# DDR32SS0_CTLPHY_WRAP_CTL_CFG_CTLCFG register map
Vendor: Texas Instruments
Registers are 32-bit, read-write, reset 0x0 unless marked. A register's access mark holds for its fields unless they carry their own. Offsets are as the file gives them; [hi:lo] are bit positions; lines under a group give offsets from that group; {n}, {i} and the like mark numbered series.

## DDR32SS0_CTLPHY_WRAP_CTL_CFG_CTLCFG (part 11 of 11)
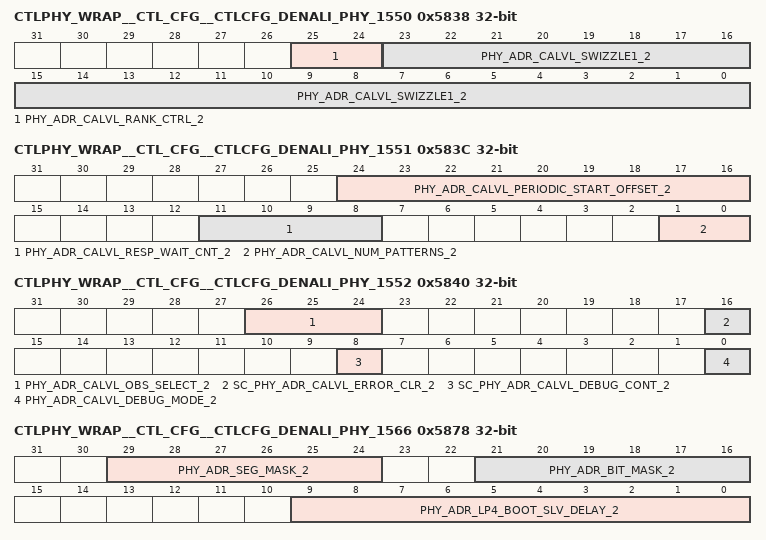
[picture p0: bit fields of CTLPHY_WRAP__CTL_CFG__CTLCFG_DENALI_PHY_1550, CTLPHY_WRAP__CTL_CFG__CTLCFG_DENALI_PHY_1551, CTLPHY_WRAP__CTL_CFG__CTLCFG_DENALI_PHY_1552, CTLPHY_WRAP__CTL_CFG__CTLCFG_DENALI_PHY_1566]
0x5838 CTLPHY_WRAP__CTL_CFG__CTLCFG_DENALI_PHY_1550
  [25:24] PHY_ADR_CALVL_RANK_CTRL_2 — CA training rank aggregation control bits for address slice 2.
  [23:0] PHY_ADR_CALVL_SWIZZLE1_2 — CA training RD DQ bit swizzle map 1 for address slice 2.
0x583C CTLPHY_WRAP__CTL_CFG__CTLCFG_DENALI_PHY_1551
  [24:16] PHY_ADR_CALVL_PERIODIC_START_OFFSET_2 — Relative offset to start periodic CALVL from previous result
  [11:8] PHY_ADR_CALVL_RESP_WAIT_CNT_2 — Number of samples to wait before sampling response during CA training for address slice 2.
  [1:0] PHY_ADR_CALVL_NUM_PATTERNS_2 — Number of patterns to use during CA training for address slice 2.
0x5840 CTLPHY_WRAP__CTL_CFG__CTLCFG_DENALI_PHY_1552 access per field
  [26:24] PHY_ADR_CALVL_OBS_SELECT_2 rw — CA bit lane to observe result from OBS0 during CA training for address slice 2.
  [16] SC_PHY_ADR_CALVL_ERROR_CLR_2 wo — Clears the CA training state machine error status for address slice 2. Set to 1 to trigger. WRITE-ONLY
  [8] SC_PHY_ADR_CALVL_DEBUG_CONT_2 wo — Allows the CA training state machine to advance [when in debug mode] for address slice 2. Set to 1 to trigger. WRITE-ONLY
  [0] PHY_ADR_CALVL_DEBUG_MODE_2 rw — Enables CA training debug mode for address slice 2. Set to 1 to enable.
0x5844 CTLPHY_WRAP__CTL_CFG__CTLCFG_DENALI_PHY_1553 ro
  [31:0] PHY_ADR_CALVL_CH0_OBS0_2 — Observation register for CA training for channel 0 slice 2. READ-ONLY
0x5848 CTLPHY_WRAP__CTL_CFG__CTLCFG_DENALI_PHY_1554 ro
  [31:0] PHY_ADR_CALVL_CH1_OBS0_2 — Observation register for CA training for channel 1 slice 2. READ-ONLY
0x584C CTLPHY_WRAP__CTL_CFG__CTLCFG_DENALI_PHY_1555 ro
  [31:0] PHY_ADR_CALVL_OBS1_2 — Observation register contains general CA training bits for slice 2. READ-ONLY
0x5850 CTLPHY_WRAP__CTL_CFG__CTLCFG_DENALI_PHY_1556 ro reset 0x100
  [31:0] PHY_ADR_CALVL_OBS2_2 — Observation register contains periodic CA training bits for slice 2. READ-ONLY
0x5854 CTLPHY_WRAP__CTL_CFG__CTLCFG_DENALI_PHY_1557
  [19:0] PHY_ADR_CALVL_FG_0_2 — CA training foreground pattern 0 for address slice 2.
0x5858 CTLPHY_WRAP__CTL_CFG__CTLCFG_DENALI_PHY_1558
  [19:0] PHY_ADR_CALVL_BG_0_2 — CA training background pattern 0 for address slice 2.
0x585C CTLPHY_WRAP__CTL_CFG__CTLCFG_DENALI_PHY_1559
  [19:0] PHY_ADR_CALVL_FG_1_2 — CA training foreground pattern 1 for address slice 2.
0x5860 CTLPHY_WRAP__CTL_CFG__CTLCFG_DENALI_PHY_1560
  [19:0] PHY_ADR_CALVL_BG_1_2 — CA training background pattern 1 for address slice 2.
0x5864 CTLPHY_WRAP__CTL_CFG__CTLCFG_DENALI_PHY_1561
  [19:0] PHY_ADR_CALVL_FG_2_2 — CA training foreground pattern 2 for address slice 2.
0x5868 CTLPHY_WRAP__CTL_CFG__CTLCFG_DENALI_PHY_1562
  [19:0] PHY_ADR_CALVL_BG_2_2 — CA training background pattern 2 for address slice 2.
0x586C CTLPHY_WRAP__CTL_CFG__CTLCFG_DENALI_PHY_1563
  [19:0] PHY_ADR_CALVL_FG_3_2 — CA training foreground pattern 3 for address slice 2.
0x5870 CTLPHY_WRAP__CTL_CFG__CTLCFG_DENALI_PHY_1564
  [19:0] PHY_ADR_CALVL_BG_3_2 — CA training background pattern 3 for address slice 2.
0x5874 CTLPHY_WRAP__CTL_CFG__CTLCFG_DENALI_PHY_1565
  [29:0] PHY_ADR_ADDR_SEL_2 — Selects which DFI address pins connect to which CA pins for LPDDR3/4 for address slice 2.
0x5878 CTLPHY_WRAP__CTL_CFG__CTLCFG_DENALI_PHY_1566
  [29:24] PHY_ADR_SEG_MASK_2 — Segment mask bit for address slice 2. Set to 1 to indicate that the bit is either CA 4 or CA 9.
  [21:16] PHY_ADR_BIT_MASK_2 — Mask bit for address slice 2. Set to 1 to indicate that the bit is used.
  [9:0] PHY_ADR_LP4_BOOT_SLV_DELAY_2 — Address target delay setting during the LPDDR4 boot frequency operation for address slice 2.
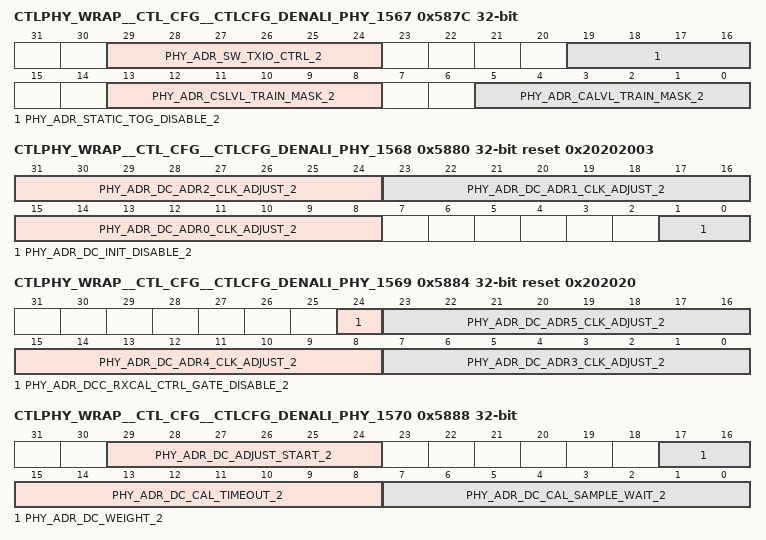
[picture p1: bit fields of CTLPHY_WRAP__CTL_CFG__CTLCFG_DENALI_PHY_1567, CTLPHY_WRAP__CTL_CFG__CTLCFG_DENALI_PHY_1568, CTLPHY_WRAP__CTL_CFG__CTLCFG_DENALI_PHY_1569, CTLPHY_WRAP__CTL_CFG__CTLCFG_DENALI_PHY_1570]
0x587C CTLPHY_WRAP__CTL_CFG__CTLCFG_DENALI_PHY_1567
  [29:24] PHY_ADR_SW_TXIO_CTRL_2 — Controls address pad output enable for address slice 2. Set to 1 to disable output enable.
  [19:16] PHY_ADR_STATIC_TOG_DISABLE_2 — Toggle control during static activity for address slice 2. Set bit to dsiable toggling, bit0: Write path delay line, bit1: Read path delay line, bit2: Read data path, bit3: clk_phy, bit4: controller delay line.
  [13:8] PHY_ADR_CSLVL_TRAIN_MASK_2 — Mask bit for CS training participation for address slice 2. Set to 1 to indicate that the bit is participating in CS training.
  [5:0] PHY_ADR_CALVL_TRAIN_MASK_2 — Mask bit for CA training participation for address slice 2. Set to 1 to indicate that the bit is participating in CA training.
0x5880 CTLPHY_WRAP__CTL_CFG__CTLCFG_DENALI_PHY_1568 reset 0x20202003
  [31:24] PHY_ADR_DC_ADR2_CLK_ADJUST_2 — Adjust value of Clock Duty Cycle Adjuster lane 2 for address slice 2.
  [23:16] PHY_ADR_DC_ADR1_CLK_ADJUST_2 — Adjust value of Clock Duty Cycle Adjuster lane 1 for address slice 2.
  [15:8] PHY_ADR_DC_ADR0_CLK_ADJUST_2 — Adjust value of Clock Duty Cycle Adjuster lane 0 for address slice 2.
  [1:0] PHY_ADR_DC_INIT_DISABLE_2 — Duty Cycle Corrector disable at initialization for address slice 2. Set to 1 to disable, bit [1] controls data path, bit [0] controls clock path.
0x5884 CTLPHY_WRAP__CTL_CFG__CTLCFG_DENALI_PHY_1569 reset 0x202020
  [24] PHY_ADR_DCC_RXCAL_CTRL_GATE_DISABLE_2 — DCC and RX_CAL clk gate disable for address slice 2. 1 = disable clk gate.
  [23:16] PHY_ADR_DC_ADR5_CLK_ADJUST_2 — Adjust value of Clock Duty Cycle Adjuster lane 5 for address slice 2.
  [15:8] PHY_ADR_DC_ADR4_CLK_ADJUST_2 — Adjust value of Clock Duty Cycle Adjuster lane 4 for address slice 2.
  [7:0] PHY_ADR_DC_ADR3_CLK_ADJUST_2 — Adjust value of Clock Duty Cycle Adjuster lane 3 for address slice 2.
0x5888 CTLPHY_WRAP__CTL_CFG__CTLCFG_DENALI_PHY_1570
  [29:24] PHY_ADR_DC_ADJUST_START_2 — DCC calibration starting value for address slice 2.
  [17:16] PHY_ADR_DC_WEIGHT_2 — DCC weighting factor base value for address slice 2.
  [15:8] PHY_ADR_DC_CAL_TIMEOUT_2 — DCC number of iterations to wait before timeout for address slice 2.
  [7:0] PHY_ADR_DC_CAL_SAMPLE_WAIT_2 — DCC cycles to wait after calibration change before sampling results for address slice 2.
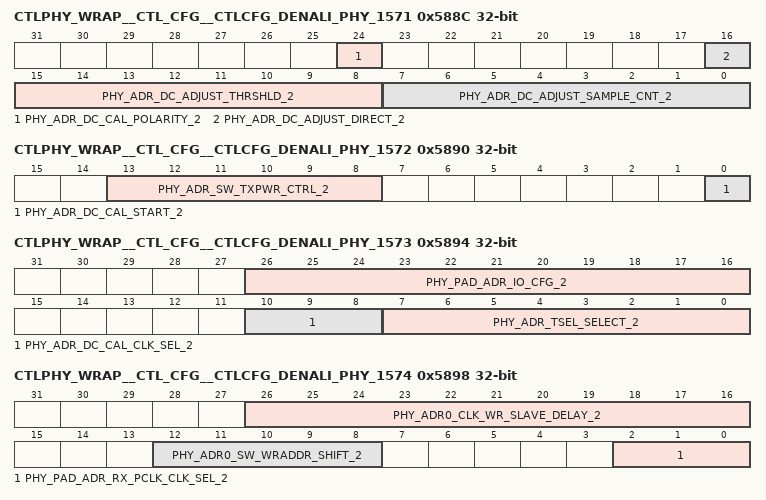
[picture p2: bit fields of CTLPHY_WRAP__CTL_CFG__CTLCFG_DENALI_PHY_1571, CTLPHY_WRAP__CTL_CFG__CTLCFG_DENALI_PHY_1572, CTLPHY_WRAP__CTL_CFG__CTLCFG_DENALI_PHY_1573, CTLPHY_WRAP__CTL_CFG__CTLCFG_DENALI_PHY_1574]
0x588C CTLPHY_WRAP__CTL_CFG__CTLCFG_DENALI_PHY_1571
  [24] PHY_ADR_DC_CAL_POLARITY_2 — DCC calibration polarity for address slice 2.
  [16] PHY_ADR_DC_ADJUST_DIRECT_2 — DCC adjust direction for address slice 2.
  [15:8] PHY_ADR_DC_ADJUST_THRSHLD_2 — DCC adjust threshold around the mid-point for address slice 2.
  [7:0] PHY_ADR_DC_ADJUST_SAMPLE_CNT_2 — DCC number of samples to take for address slice 2.
0x5890 CTLPHY_WRAP__CTL_CFG__CTLCFG_DENALI_PHY_1572
  [13:8] PHY_ADR_SW_TXPWR_CTRL_2 — Disable address output enables in deep sleep mode for address slice 2.
  [0] PHY_ADR_DC_CAL_START_2 — DCC Manual trigger for address slice 2.
0x5894 CTLPHY_WRAP__CTL_CFG__CTLCFG_DENALI_PHY_1573
  [26:16] PHY_PAD_ADR_IO_CFG_2 — Controls I/O pads for address pad for address slice 2. Bits [10:5] = Park value, bits [4] park override, bits [2:0] clk divider.
  [10:8] PHY_ADR_DC_CAL_CLK_SEL_2 — DCC CAL clock for address slice 2.
  [7:0] PHY_ADR_TSEL_SELECT_2 — Tsel select values for address slice 2.
0x5898 CTLPHY_WRAP__CTL_CFG__CTLCFG_DENALI_PHY_1574
  [26:16] PHY_ADR0_CLK_WR_SLAVE_DELAY_2 — CA bit 0 target delay setting for address slice 2.
  [12:8] PHY_ADR0_SW_WRADDR_SHIFT_2 — Manual override of CA bit 0 of automatic half_cycle_shift/cycle_shift for address slice 2. Bit [0] enables override of half_cycle_shift. Bit [1] is the half_cycle_shift value. Bit [2] enables override of cycle shift. Bits [4:3] is the cycle_shift value. For bits [4:3], clear to 0x0 for no offset, program to 0x1 for -1 cycle, program to 0x2 for +1 cycle, or program to 0x3 for -2 cycles.
  [2:0] PHY_PAD_ADR_RX_PCLK_CLK_SEL_2 — Reserved for address slice 2.
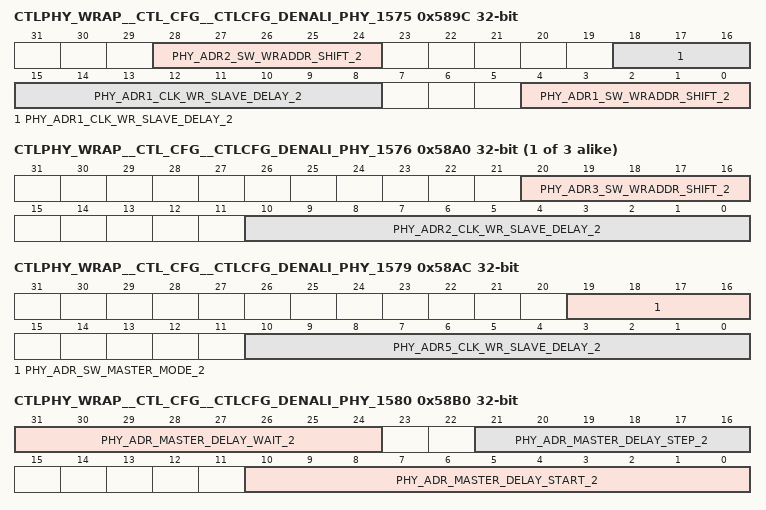
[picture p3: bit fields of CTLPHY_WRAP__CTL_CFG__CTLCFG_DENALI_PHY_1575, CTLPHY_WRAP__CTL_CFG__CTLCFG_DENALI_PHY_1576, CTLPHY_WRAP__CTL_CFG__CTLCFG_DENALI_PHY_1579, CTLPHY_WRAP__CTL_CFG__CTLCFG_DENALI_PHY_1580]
0x589C CTLPHY_WRAP__CTL_CFG__CTLCFG_DENALI_PHY_1575
  [28:24] PHY_ADR2_SW_WRADDR_SHIFT_2 — Manual override of CA bit 2 of automatic half_cycle_shift/cycle_shift for address slice 2. Bit [0] enables override of half_cycle_shift. Bit [1] is the half_cycle_shift value. Bit [2] enables override of cycle shift. Bits [4:3] is the cycle_shift value. For bits [4:3], clear to 0x0 for no offset, program to 0x1 for -1 cycle, program to 0x2 for +1 cycle, or program to 0x3 for -2 cycles.
  [18:8] PHY_ADR1_CLK_WR_SLAVE_DELAY_2 — CA bit 1 target delay setting for address slice 2.
  [4:0] PHY_ADR1_SW_WRADDR_SHIFT_2 — Manual override of CA bit 1 of automatic half_cycle_shift/cycle_shift for address slice 2. Bit [0] enables override of half_cycle_shift. Bit [1] is the half_cycle_shift value. Bit [2] enables override of cycle shift. Bits [4:3] is the cycle_shift value. For bits [4:3], clear to 0x0 for no offset, program to 0x1 for -1 cycle, program to 0x2 for +1 cycle, or program to 0x3 for -2 cycles.
{0x4000+4i} CTLPHY_WRAP__CTL_CFG__CTLCFG_DENALI_PHY_{i} (i=1576..1578)
  [20:16] PHY_ADR{i-1573}_SW_WRADDR_SHIFT_2 — Manual override of CA bit {i-1573} of automatic half_cycle_shift/cycle_shift for address slice 2. Bit [0] enables override of half_cycle_shift. Bit [1] is the half_cycle_shift value. Bit [2] enables override of cycle shift. Bits [4:3] is the cycle_shift value. For bits [4:3], clear to 0x0 for no offset, program to 0x1 for -1 cycle, program to 0x2 for +1 cycle, or program to 0x3 for -2 cycles.
  [10:0] PHY_ADR{i-1574}_CLK_WR_SLAVE_DELAY_2 — CA bit {i-1574} target delay setting for address slice 2.
0x58AC CTLPHY_WRAP__CTL_CFG__CTLCFG_DENALI_PHY_1579
  [19:16] PHY_ADR_SW_MASTER_MODE_2 — Controller delay line override settings for address slice 2. Bit [0] enables software half clock mode. Bit [1] is the software half clock mode value. Bit [2] enables software bypass mode. Bit [3] is the software bypass mode value.
  [10:0] PHY_ADR5_CLK_WR_SLAVE_DELAY_2 — CA bit 5 target delay setting for address slice 2.
0x58B0 CTLPHY_WRAP__CTL_CFG__CTLCFG_DENALI_PHY_1580
  [31:24] PHY_ADR_MASTER_DELAY_WAIT_2 — Wait cycles for controller delay line locking algorithm for address slice 2. Bits [3:0] is the cycle wait count after a calibration clock setting change. Bits [7:4] is the cycle wait count after a controller delay setting change.
  [21:16] PHY_ADR_MASTER_DELAY_STEP_2 — Incremental step size for controller delay line locking algorithm for address slice 2.
  [10:0] PHY_ADR_MASTER_DELAY_START_2 — Start value for controller delay line locking algorithm for address slice 2.
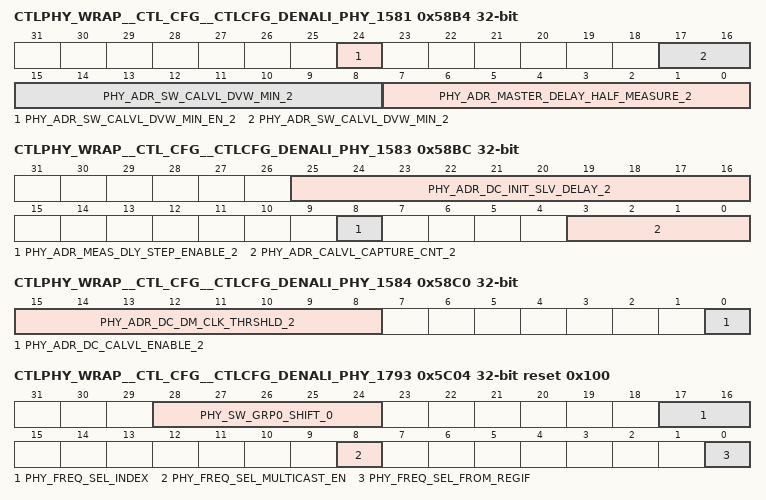
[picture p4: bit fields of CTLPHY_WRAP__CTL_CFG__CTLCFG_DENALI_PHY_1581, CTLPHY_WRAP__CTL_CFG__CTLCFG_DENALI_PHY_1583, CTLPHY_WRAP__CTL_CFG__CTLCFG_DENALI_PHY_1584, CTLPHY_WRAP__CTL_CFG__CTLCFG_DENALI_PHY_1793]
0x58B4 CTLPHY_WRAP__CTL_CFG__CTLCFG_DENALI_PHY_1581
  [24] PHY_ADR_SW_CALVL_DVW_MIN_EN_2 — Enables the software override data valid window size during CA training for address slice 2.
  [17:8] PHY_ADR_SW_CALVL_DVW_MIN_2 — Sets the software override data valid window size during CA training for address slice 2.
  [7:0] PHY_ADR_MASTER_DELAY_HALF_MEASURE_2 — Defines the number of delay line elements to be considered in determing whether to lock to a half clock cycle for the controller in address slice 2
0x58B8 CTLPHY_WRAP__CTL_CFG__CTLCFG_DENALI_PHY_1582
  [3:0] PHY_ADR_CALVL_DLY_STEP_2 — Sets the delay step size plus 1 during CA training for address slice 2.
0x58BC CTLPHY_WRAP__CTL_CFG__CTLCFG_DENALI_PHY_1583
  [25:16] PHY_ADR_DC_INIT_SLV_DELAY_2 — DCC initialization value of write ADDR target delay for address slice 2.
  [8] PHY_ADR_MEAS_DLY_STEP_ENABLE_2 — Enables delay parameter setting using phy_adr_meas_dly_step_value for address slice 2.
  [3:0] PHY_ADR_CALVL_CAPTURE_CNT_2 — Number of samples to take at each ADDR target delay setting during CA training for address slice 2.
0x58C0 CTLPHY_WRAP__CTL_CFG__CTLCFG_DENALI_PHY_1584
  [15:8] PHY_ADR_DC_DM_CLK_THRSHLD_2 — DCC clock measurement cell threshold offset for address slice 2.
  [0] PHY_ADR_DC_CALVL_ENABLE_2 — DCC enable duty cycle adjust during CA leveling for address slice 2.
0x5C00 CTLPHY_WRAP__CTL_CFG__CTLCFG_DENALI_PHY_1792
  [1:0] PHY_FREQ_SEL — Specifies which copy of the frequency-dependent timing parameters will be used by the PHY.
0x5C04 CTLPHY_WRAP__CTL_CFG__CTLCFG_DENALI_PHY_1793 reset 0x100
  [28:24] PHY_SW_GRP0_SHIFT_0 — Address slice target delay setting for address slice 4.
  [17:16] PHY_FREQ_SEL_INDEX — Selects which frequency set to update when PHY_FREQ_SEL_MULTICAST_EN is not set.
  [8] PHY_FREQ_SEL_MULTICAST_EN — When set, a register write will update parameters for all frequency sets simultaneously. Set to 1 to enable.
  [0] PHY_FREQ_SEL_FROM_REGIF — Indicates which source is used to select the frequency copy. When set to 1, the frequency select source is given by parameter PHY_FREQ_SEL from register I/F. When cleared to 0, the frequency select source is the PHY input signal dfi_frequency
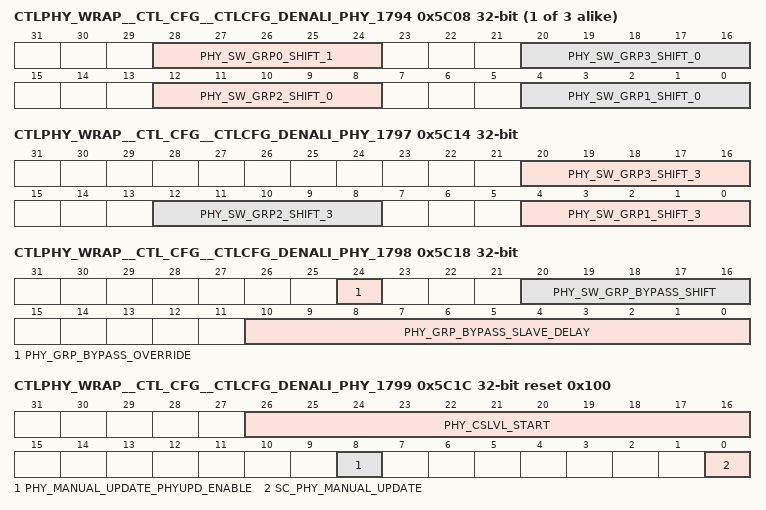
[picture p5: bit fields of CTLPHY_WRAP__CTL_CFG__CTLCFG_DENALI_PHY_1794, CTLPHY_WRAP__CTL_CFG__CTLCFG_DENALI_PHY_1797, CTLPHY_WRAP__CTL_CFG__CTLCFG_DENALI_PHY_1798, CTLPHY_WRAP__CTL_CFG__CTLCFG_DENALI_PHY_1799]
{0x4000+4i} CTLPHY_WRAP__CTL_CFG__CTLCFG_DENALI_PHY_{i} (i=1794..1796)
  [28:24] PHY_SW_GRP0_SHIFT_{i-1793} — Address slice target delay setting for address slice 4.
  [20:16] PHY_SW_GRP3_SHIFT_{i-1794} — Address slice target delay setting for address slice 4.
  [12:8] PHY_SW_GRP2_SHIFT_{i-1794} — Address slice target delay setting for address slice 4.
  [4:0] PHY_SW_GRP1_SHIFT_{i-1794} — Address slice target delay setting for address slice 4.
0x5C14 CTLPHY_WRAP__CTL_CFG__CTLCFG_DENALI_PHY_1797
  [20:16] PHY_SW_GRP3_SHIFT_3 — Address slice target delay setting for address slice 4.
  [12:8] PHY_SW_GRP2_SHIFT_3 — Address slice target delay setting for address slice 4.
  [4:0] PHY_SW_GRP1_SHIFT_3 — Address slice target delay setting for address slice 4.
0x5C18 CTLPHY_WRAP__CTL_CFG__CTLCFG_DENALI_PHY_1798
  [24] PHY_GRP_BYPASS_OVERRIDE — Address/control group slice bypass mode override setting.
  [20:16] PHY_SW_GRP_BYPASS_SHIFT — Address/control group slice bypass mode shift settings.
  [10:0] PHY_GRP_BYPASS_SLAVE_DELAY — Address/control group slice bypass mode target delay setting.
0x5C1C CTLPHY_WRAP__CTL_CFG__CTLCFG_DENALI_PHY_1799 access per field reset 0x100
  [26:16] PHY_CSLVL_START rw — Defines the CS training DDL start value.
  [8] PHY_MANUAL_UPDATE_PHYUPD_ENABLE rw — Manual update selection of all target delay line settings. Set 1 to assert phyupd_req and wait phyupd_ack to update delay line, set 0 to update delay line directly.
  [0] SC_PHY_MANUAL_UPDATE wo — Manual update of all target delay line settings. Set to 1 to trigger. WRITE-ONLY
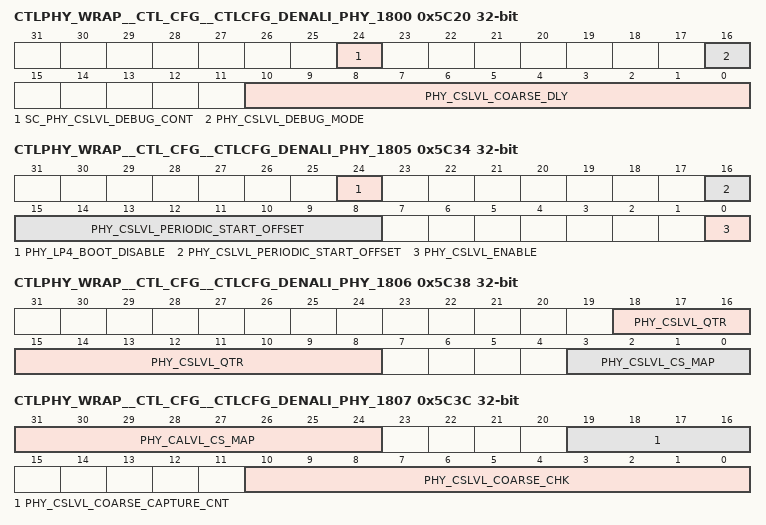
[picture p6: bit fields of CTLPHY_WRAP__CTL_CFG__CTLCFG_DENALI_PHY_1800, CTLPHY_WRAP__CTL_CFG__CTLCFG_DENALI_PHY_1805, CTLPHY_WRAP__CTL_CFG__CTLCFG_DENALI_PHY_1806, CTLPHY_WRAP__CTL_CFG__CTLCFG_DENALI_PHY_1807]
0x5C20 CTLPHY_WRAP__CTL_CFG__CTLCFG_DENALI_PHY_1800 access per field
  [24] SC_PHY_CSLVL_DEBUG_CONT wo — Allows the CS training state machine to advance [when in debug mode]. Set to 1 to trigger. WRITE-ONLY
  [16] PHY_CSLVL_DEBUG_MODE rw — Enables CS training debug mode. Set to 1 to enable.
  [10:0] PHY_CSLVL_COARSE_DLY rw — Defines the CS training DDL coarse cycle delay value.
0x5C24 CTLPHY_WRAP__CTL_CFG__CTLCFG_DENALI_PHY_1801 wo
  [0] SC_PHY_CSLVL_ERROR_CLR — Clears the CS training state machine error status. Set to 1 to trigger. WRITE-ONLY
0x5C28 CTLPHY_WRAP__CTL_CFG__CTLCFG_DENALI_PHY_1802 ro reset 0x6800000
  [31:0] PHY_CSLVL_OBS0 — Observation register for CS training delay values. READ-ONLY
0x5C2C CTLPHY_WRAP__CTL_CFG__CTLCFG_DENALI_PHY_1803 ro
  [31:0] PHY_CSLVL_OBS1 — Observation register for CS training algorithm status. READ-ONLY
0x5C30 CTLPHY_WRAP__CTL_CFG__CTLCFG_DENALI_PHY_1804 ro
  [31:0] PHY_CSLVL_OBS2 — Observation register for periodic CS training delay values. READ-ONLY
0x5C34 CTLPHY_WRAP__CTL_CFG__CTLCFG_DENALI_PHY_1805
  [24] PHY_LP4_BOOT_DISABLE — Controls the handling of the DFI frequency. When set to 1, DFI frequency 0 is considered the first operational frequency. When cleared to 0, DFI frequency 0 is the boot frequency and other DFI frequency values are operational frequencies. Must be cleared to 0 for LPDDR3 devices operating in an LPDDR4 capable configuration.
  [16:8] PHY_CSLVL_PERIODIC_START_OFFSET — Defines the relative offset from previous LE and TE to start periodic CSLVL with.
  [0] PHY_CSLVL_ENABLE — CS training enable. Set to 1 to enable CS training during CA training.
0x5C38 CTLPHY_WRAP__CTL_CFG__CTLCFG_DENALI_PHY_1806
  [18:8] PHY_CSLVL_QTR — Defines the CS training DDL 1/4 cycle delay value.
  [3:0] PHY_CSLVL_CS_MAP — CS training map. Set each CS bit to 1 to allow that CS to participate in CS training results. NOT CURRENTLY USED.
0x5C3C CTLPHY_WRAP__CTL_CFG__CTLCFG_DENALI_PHY_1807
  [31:24] PHY_CALVL_CS_MAP — Defines the slice numbers associated with each CS during CA training.
  [19:16] PHY_CSLVL_COARSE_CAPTURE_CNT — Defines the number of samples to take at each GRP target delay setting during CS training coarse CA training.
  [10:0] PHY_CSLVL_COARSE_CHK — Defines the CS training coarse CA training DDL 1/16th cycle delay value.
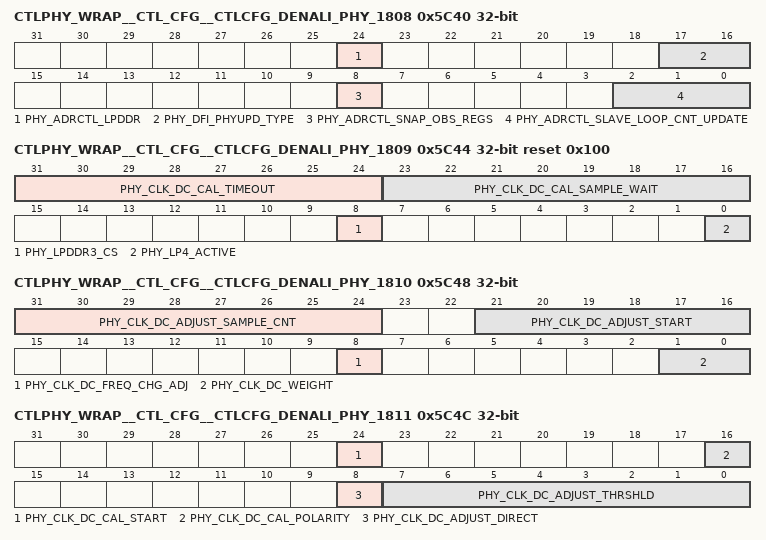
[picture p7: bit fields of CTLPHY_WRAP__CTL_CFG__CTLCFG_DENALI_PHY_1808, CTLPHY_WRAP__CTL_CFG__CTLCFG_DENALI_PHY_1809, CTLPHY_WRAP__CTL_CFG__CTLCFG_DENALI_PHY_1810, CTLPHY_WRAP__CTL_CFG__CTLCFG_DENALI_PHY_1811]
0x5C40 CTLPHY_WRAP__CTL_CFG__CTLCFG_DENALI_PHY_1808 access per field
  [24] PHY_ADRCTL_LPDDR rw — Adds a cycle of delay for the address/control slices to match the address slice.
  [17:16] PHY_DFI_PHYUPD_TYPE rw — Defines the value of the dfi_phyupd_type output signal to MC.
  [8] PHY_ADRCTL_SNAP_OBS_REGS wo — Initiates a snapshot of the internal observation registers for the address/control block. Set to 1 to trigger. WRITE-ONLY
  [2:0] PHY_ADRCTL_SLAVE_LOOP_CNT_UPDATE rw — Reserved for the address/control controller.
0x5C44 CTLPHY_WRAP__CTL_CFG__CTLCFG_DENALI_PHY_1809 reset 0x100
  [31:24] PHY_CLK_DC_CAL_TIMEOUT — Duty cycle correction maximum iteration count.
  [23:16] PHY_CLK_DC_CAL_SAMPLE_WAIT — Number of cal clock cycles to wait for a sample to be taken.
  [8] PHY_LPDDR3_CS — Alters reset state polarity for LPDDR chip selects.
  [0] PHY_LP4_ACTIVE — Indicates an LPDDR4 device is connected to the PHY.
0x5C48 CTLPHY_WRAP__CTL_CFG__CTLCFG_DENALI_PHY_1810
  [31:24] PHY_CLK_DC_ADJUST_SAMPLE_CNT — Duty cycle correction algorithm sample count per adjustment setting.
  [21:16] PHY_CLK_DC_ADJUST_START — Duty cycle correction algorithm adjustment starting value.
  [8] PHY_CLK_DC_FREQ_CHG_ADJ — Duty cycle correction during frequency change control.
  [1:0] PHY_CLK_DC_WEIGHT — Duty cycle correction weighting factor base value.
0x5C4C CTLPHY_WRAP__CTL_CFG__CTLCFG_DENALI_PHY_1811
  [24] PHY_CLK_DC_CAL_START — Duty cycle correction calibration manual start.
  [16] PHY_CLK_DC_CAL_POLARITY — Duty cycle correction algorithm measurement polarity.
  [8] PHY_CLK_DC_ADJUST_DIRECT — Duty cycle correction algorithm adjustment direction.
  [7:0] PHY_CLK_DC_ADJUST_THRSHLD — Duty cycle correction algorithm threshold delta comparison.
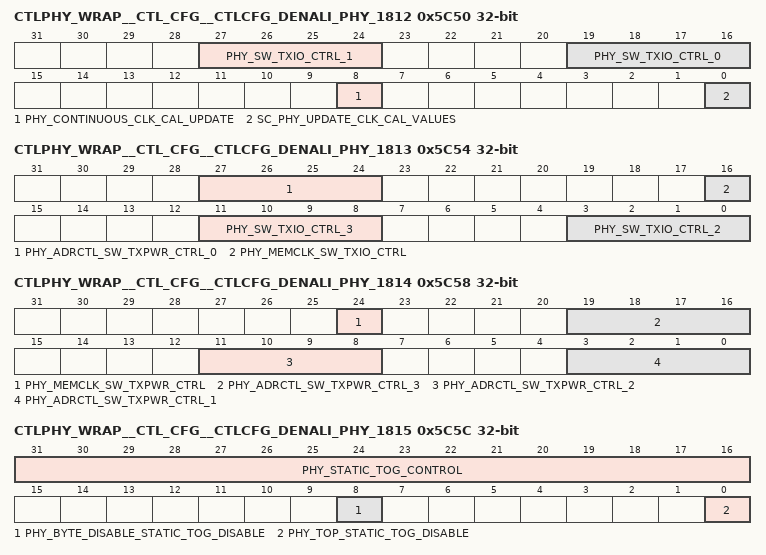
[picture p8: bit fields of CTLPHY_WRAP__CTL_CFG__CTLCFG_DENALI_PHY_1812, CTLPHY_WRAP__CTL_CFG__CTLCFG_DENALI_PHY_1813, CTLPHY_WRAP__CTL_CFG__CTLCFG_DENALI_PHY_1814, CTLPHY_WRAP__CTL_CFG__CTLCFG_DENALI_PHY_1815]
0x5C50 CTLPHY_WRAP__CTL_CFG__CTLCFG_DENALI_PHY_1812 access per field
  [27:24] PHY_SW_TXIO_CTRL_1 rw — This register is used to control if command pad [CS/RAS...] should be shutoff for TX mode.
  [19:16] PHY_SW_TXIO_CTRL_0 rw — This register is used to control if command pad [CS/RAS...] should be shutoff for TX mode.
  [8] PHY_CONTINUOUS_CLK_CAL_UPDATE rw — Continuous update of all latest PVTP,PVTN and PVTR values to the CLK IO pads. Set to 1 to keep this enabled.
  [0] SC_PHY_UPDATE_CLK_CAL_VALUES wo — Manual update of all latest PVTP,PVTN and PVTR values to the CLK IO pads. Set to 1 to trigger. WRITE-ONLY
0x5C54 CTLPHY_WRAP__CTL_CFG__CTLCFG_DENALI_PHY_1813
  [27:24] PHY_ADRCTL_SW_TXPWR_CTRL_0 — This register is used to control if address/command pad [address/CS/RAS...] should be shutoff for TX mode in deep sleep mode.
  [16] PHY_MEMCLK_SW_TXIO_CTRL — This register is used to control if clk pads should be shutoff for TX mode.
  [11:8] PHY_SW_TXIO_CTRL_3 — This register is used to control if command pad [CS/RAS...] should be shutoff for TX mode.
  [3:0] PHY_SW_TXIO_CTRL_2 — This register is used to control if command pad [CS/RAS...] should be shutoff for TX mode.
0x5C58 CTLPHY_WRAP__CTL_CFG__CTLCFG_DENALI_PHY_1814
  [24] PHY_MEMCLK_SW_TXPWR_CTRL — This register is used to control if clk pads should be shutoff for TX mode in deep sleep mode.
  [19:16] PHY_ADRCTL_SW_TXPWR_CTRL_3 — This register is used to control if address/command pad [address/CS/RAS...] should be shutoff for TX mode in deep sleep mode.
  [11:8] PHY_ADRCTL_SW_TXPWR_CTRL_2 — This register is used to control if address/command pad [address/CS/RAS...] should be shutoff for TX mode in deep sleep mode.
  [3:0] PHY_ADRCTL_SW_TXPWR_CTRL_1 — This register is used to control if address/command pad [address/CS/RAS...] should be shutoff for TX mode in deep sleep mode.
0x5C5C CTLPHY_WRAP__CTL_CFG__CTLCFG_DENALI_PHY_1815
  [31:16] PHY_STATIC_TOG_CONTROL — Clock divider to create toggle signal. Use long counter as the base.
  [8] PHY_BYTE_DISABLE_STATIC_TOG_DISABLE — Control to disable the toggle signal for data slice during static activity when dfi_data_byte_disable is asserted.
  [0] PHY_TOP_STATIC_TOG_DISABLE — Disables the generation of the toggle for static clock based paths in the PHY to prevent assymetric aging.
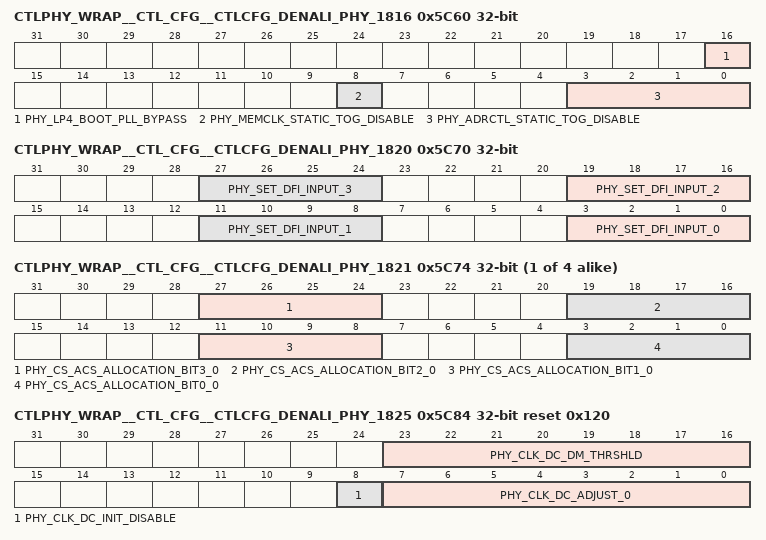
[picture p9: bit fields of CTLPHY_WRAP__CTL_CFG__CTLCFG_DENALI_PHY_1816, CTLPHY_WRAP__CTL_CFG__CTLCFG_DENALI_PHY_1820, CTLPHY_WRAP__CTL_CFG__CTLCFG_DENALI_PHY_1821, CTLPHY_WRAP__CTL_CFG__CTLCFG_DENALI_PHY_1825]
0x5C60 CTLPHY_WRAP__CTL_CFG__CTLCFG_DENALI_PHY_1816
  [16] PHY_LP4_BOOT_PLL_BYPASS — PHY clock PLL bypass select.
  [8] PHY_MEMCLK_STATIC_TOG_DISABLE — Control to disable toggle during static activity. bit0: clock disable.
  [3:0] PHY_ADRCTL_STATIC_TOG_DISABLE — Control to disable toggle during static activity. bit0: Write path delay line disable; bit1: clock disable; bit2: adrctl controller delay line disable [if exists]; bit3: adrctl misc core clk disable.[if exists]
0x5C64 CTLPHY_WRAP__CTL_CFG__CTLCFG_DENALI_PHY_1817 ro reset 0x10082650
  [31:0] PHY_CLK_SWITCH_OBS — Observation register for Clock switch state machine READ-ONLY
0x5C68 CTLPHY_WRAP__CTL_CFG__CTLCFG_DENALI_PHY_1818
  [15:0] PHY_PLL_WAIT — PHY clock PLL wait time after locking.
0x5C6C CTLPHY_WRAP__CTL_CFG__CTLCFG_DENALI_PHY_1819
  [0] PHY_SW_PLL_BYPASS — PHY clock PLL bypass select.
0x5C70 CTLPHY_WRAP__CTL_CFG__CTLCFG_DENALI_PHY_1820
  [8n+3:8n] PHY_SET_DFI_INPUT_{n} (n=0..3) — Used to indicate the default value of the adrctl slice bits.
{0x4000+4i} CTLPHY_WRAP__CTL_CFG__CTLCFG_DENALI_PHY_{i} (i=1821..1824)
  [27:24] PHY_CS_ACS_ALLOCATION_BIT3_{i-1821} — The map for which chip select is associated with each bit in the adrctl slice {i-1821}. Bit [n], 1 means cs[n]'s signal[CS/CKE/ODT/RST] is allocated on ACS_{i-1821} bit3, 0 means cs[n]'s signal[CS/CKE/ODT/RST] is not tranfser on ACS_{i-1821}, if the accroding cs[n]'s training is not enabled, need to set the value to all 1s.
  [19:16] PHY_CS_ACS_ALLOCATION_BIT2_{i-1821} — The map for which chip select is associated with each bit in the adrctl slice {i-1821}. Bit [n], 1 means cs[n]'s signal[CS/CKE/ODT/RST] is allocated on ACS_{i-1821} bit2 , 0 means cs[n]'s signal[CS/CKE/ODT/RST] is not tranfser on ACS_{i-1821}, if the accroding cs[n]'s training is not enabled, need to set the value to all 1s.
  [11:8] PHY_CS_ACS_ALLOCATION_BIT1_{i-1821} — The map for which chip select is associated with each bit in the adrctl slice {i-1821}. Bit [n], 1 means cs[n]'s signal[CS/CKE/ODT/RST] is allocated on ACS_{i-1821} bit1, 0 means cs[n]'s signal[CS/CKE/ODT/RST] is not tranfser on ACS_{i-1821}, if the accroding cs[n]'s training is not enabled, need to set the value to all 1s.
  [3:0] PHY_CS_ACS_ALLOCATION_BIT0_{i-1821} — The map for which chip select is associated with each bit in the adrctl slice {i-1821}. Bit [n], 1 means cs[n]'s signal[CS/CKE/ODT/RST] is allocated on ACS_{i-1821} bit0, 0 means cs[n]'s signal[CS/CKE/ODT/RST] is not tranfser on ACS_{i-1821}, if the accroding cs[n]'s training is not enabled, need to set the value to all 1s.
0x5C84 CTLPHY_WRAP__CTL_CFG__CTLCFG_DENALI_PHY_1825 reset 0x120
  [23:16] PHY_CLK_DC_DM_THRSHLD — Data measurement cell threshold offset.
  [8] PHY_CLK_DC_INIT_DISABLE — Disable duty cycle adjust at initialization.
  [7:0] PHY_CLK_DC_ADJUST_0 — Adjust value of Duty Cycle Adjuster for clock slice 0.
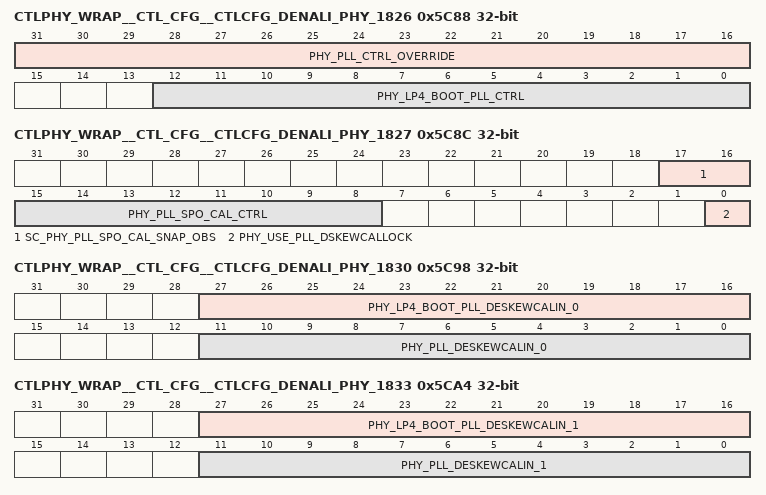
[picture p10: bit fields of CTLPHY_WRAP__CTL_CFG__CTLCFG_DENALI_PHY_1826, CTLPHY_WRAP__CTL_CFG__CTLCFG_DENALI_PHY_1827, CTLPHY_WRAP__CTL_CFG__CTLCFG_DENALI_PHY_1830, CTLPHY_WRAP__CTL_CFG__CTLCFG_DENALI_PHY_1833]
0x5C88 CTLPHY_WRAP__CTL_CFG__CTLCFG_DENALI_PHY_1826
  [31:16] PHY_PLL_CTRL_OVERRIDE — Individual PHY clock PLL control overrides.
  [12:0] PHY_LP4_BOOT_PLL_CTRL — PHY deskew PLL controls for LPDDR4 boot frequency.
0x5C8C CTLPHY_WRAP__CTL_CFG__CTLCFG_DENALI_PHY_1827 access per field
  [17:16] SC_PHY_PLL_SPO_CAL_SNAP_OBS wo — Register command to take a snapshot of PLL output. WRITE-ONLY
  [15:8] PHY_PLL_SPO_CAL_CTRL rw — PLL SPO Cal controls.
  [0] PHY_USE_PLL_DSKEWCALLOCK rw — Use DSKEWCALLOCK or not.
0x5C90 CTLPHY_WRAP__CTL_CFG__CTLCFG_DENALI_PHY_1828 ro
  [15:0] PHY_PLL_OBS_0 — PHY TOP level clock PLL_0 observe values. READ-ONLY
0x5C94 CTLPHY_WRAP__CTL_CFG__CTLCFG_DENALI_PHY_1829 ro
  [16:0] PHY_PLL_SPO_CAL_OBS_0 — PHY TOP level PLL_0 SPO Cal observe values. READ-ONLY
0x5C98 CTLPHY_WRAP__CTL_CFG__CTLCFG_DENALI_PHY_1830
  [27:16] PHY_LP4_BOOT_PLL_DESKEWCALIN_0 — PHY TOP level PLL_0 lpddr4 boot deskewcal in values.
  [11:0] PHY_PLL_DESKEWCALIN_0 — PHY TOP level PLL_0 deskewcal in values.
0x5C9C CTLPHY_WRAP__CTL_CFG__CTLCFG_DENALI_PHY_1831 ro
  [15:0] PHY_PLL_OBS_1 — PHY TOP level clock PLL_1 observe values. READ-ONLY
0x5CA0 CTLPHY_WRAP__CTL_CFG__CTLCFG_DENALI_PHY_1832 ro
  [16:0] PHY_PLL_SPO_CAL_OBS_1 — PHY TOP level PLL_1 SPO Cal observe values. READ-ONLY
0x5CA4 CTLPHY_WRAP__CTL_CFG__CTLCFG_DENALI_PHY_1833
  [27:16] PHY_LP4_BOOT_PLL_DESKEWCALIN_1 — PHY TOP level PLL_1 lpddr4 boot deskewcal in values.
  [11:0] PHY_PLL_DESKEWCALIN_1 — PHY TOP level PLL_1 deskewcal in values.
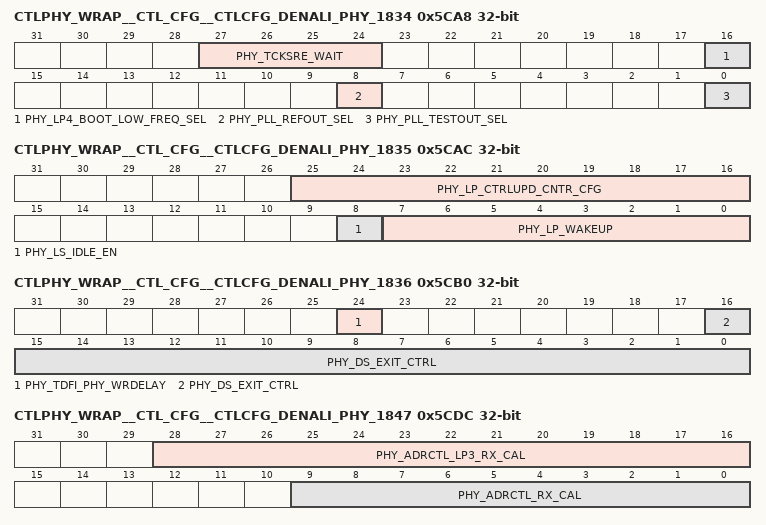
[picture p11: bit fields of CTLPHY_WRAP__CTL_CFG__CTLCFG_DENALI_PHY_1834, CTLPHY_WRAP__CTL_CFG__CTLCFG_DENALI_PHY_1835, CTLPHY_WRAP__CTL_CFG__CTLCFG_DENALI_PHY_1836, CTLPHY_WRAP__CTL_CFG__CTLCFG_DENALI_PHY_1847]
0x5CA8 CTLPHY_WRAP__CTL_CFG__CTLCFG_DENALI_PHY_1834
  [27:24] PHY_TCKSRE_WAIT — Specifies the number of cycles the PHY should wait before turning off the PLL for a deep sleep or DFS event.
  [16] PHY_LP4_BOOT_LOW_FREQ_SEL — Control the PLL domain enter/exit from the negative clock edge for LPDDR4 boot frequency.
  [8] PHY_PLL_REFOUT_SEL — PHY PLL refout select.
  [0] PHY_PLL_TESTOUT_SEL — PHY PLL testout select.
0x5CAC CTLPHY_WRAP__CTL_CFG__CTLCFG_DENALI_PHY_1835
  [25:16] PHY_LP_CTRLUPD_CNTR_CFG — Specifies the number of cycles the PHY takes from light sleep req deassert to ack deassert in low power mode.
  [8] PHY_LS_IDLE_EN — Indicates the Reduced Idle Power State is enabled in low power mode.
  [7:0] PHY_LP_WAKEUP — Specifies the number of cycles the PHY takes to wakeup in low power mode.
0x5CB0 CTLPHY_WRAP__CTL_CFG__CTLCFG_DENALI_PHY_1836
  [24] PHY_TDFI_PHY_WRDELAY — DFI timing parameter TDFI_PHY_WRDELAY.
  [16:0] PHY_DS_EXIT_CTRL — Controls to reduce the deep sleep exit latency, when bit 16 is 1 deep sleep exit ack won't wait controller delay line lock.
0x5CB4 CTLPHY_WRAP__CTL_CFG__CTLCFG_DENALI_PHY_1837 reset 0x4410
  [17:0] PHY_PAD_FDBK_TERM — Controls term settings for gate feedback pads.
0x5CB8 CTLPHY_WRAP__CTL_CFG__CTLCFG_DENALI_PHY_1838 reset 0x4410
  [16:0] PHY_PAD_DATA_TERM — Controls term settings for data pads.
0x5CBC CTLPHY_WRAP__CTL_CFG__CTLCFG_DENALI_PHY_1839 reset 0x4410
  [16:0] PHY_PAD_DQS_TERM — Controls term settings for dqs pads.
0x5CC0 CTLPHY_WRAP__CTL_CFG__CTLCFG_DENALI_PHY_1840 reset 0x4410
  [17:0] PHY_PAD_ADDR_TERM — Controls term settings for the address/control pads.
0x5CC4 CTLPHY_WRAP__CTL_CFG__CTLCFG_DENALI_PHY_1841 reset 0x4410
  [17:0] PHY_PAD_CLK_TERM — Controls term settings for clock pads.
0x5CC8 CTLPHY_WRAP__CTL_CFG__CTLCFG_DENALI_PHY_1842 reset 0x4410
  [17:0] PHY_PAD_ERR_TERM — Controls term settings for error pads.
0x5CCC CTLPHY_WRAP__CTL_CFG__CTLCFG_DENALI_PHY_1843 reset 0x4410
  [17:0] PHY_PAD_CKE_TERM — Controls term settings for cke pads.
0x5CD0 CTLPHY_WRAP__CTL_CFG__CTLCFG_DENALI_PHY_1844 reset 0x4410
  [17:0] PHY_PAD_RST_TERM — Controls term settings for reset_n pads.
0x5CD4 CTLPHY_WRAP__CTL_CFG__CTLCFG_DENALI_PHY_1845 reset 0x4410
  [17:0] PHY_PAD_CS_TERM — Controls term settings for cs pads.
0x5CD8 CTLPHY_WRAP__CTL_CFG__CTLCFG_DENALI_PHY_1846 reset 0x4410
  [17:0] PHY_PAD_ODT_TERM — Controls term settings for odt pads.
0x5CDC CTLPHY_WRAP__CTL_CFG__CTLCFG_DENALI_PHY_1847
  [28:16] PHY_ADRCTL_LP3_RX_CAL — PHY CKE/RESET_N RX calibration controls.
  [9:0] PHY_ADRCTL_RX_CAL — PHY address/control RX calibration controls.
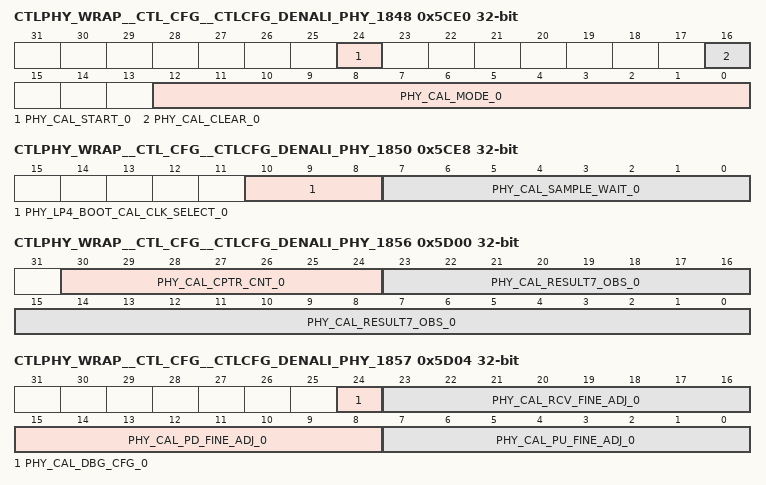
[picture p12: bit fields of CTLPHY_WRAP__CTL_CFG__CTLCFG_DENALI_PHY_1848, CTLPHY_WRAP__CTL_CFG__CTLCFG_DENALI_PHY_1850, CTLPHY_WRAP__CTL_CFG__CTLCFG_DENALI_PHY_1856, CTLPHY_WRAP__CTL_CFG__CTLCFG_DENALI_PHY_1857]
0x5CE0 CTLPHY_WRAP__CTL_CFG__CTLCFG_DENALI_PHY_1848 access per field
  [24] PHY_CAL_START_0 wo — Manual start for the pad calibration state machine for block 0. Set to 1 to trigger. WRITE-ONLY
  [16] PHY_CAL_CLEAR_0 wo — Clear the pad calibration state machine and results for block 0. Set to 1 to trigger. WRITE-ONLY
  [12:0] PHY_CAL_MODE_0 rw — Pad calibration mode bits for block 0. Bit [0] disables pad calibration upon initialization. Bit [1] enables automatic interval based calibration. Bits [3:2] set the base interval for the interval counter. Bits [7:4] are direct connections to pad control signals.
0x5CE4 CTLPHY_WRAP__CTL_CFG__CTLCFG_DENALI_PHY_1849
  [31:0] PHY_CAL_INTERVAL_COUNT_0 — Pad calibration interval counter compare value for block 0.
0x5CE8 CTLPHY_WRAP__CTL_CFG__CTLCFG_DENALI_PHY_1850
  [10:8] PHY_LP4_BOOT_CAL_CLK_SELECT_0 — Pad calibration pad clock frequency select setting for LPDDR4 boot frequency for block 0.
  [7:0] PHY_CAL_SAMPLE_WAIT_0 — Pad calibration state machine wait count in pad clock cycles for block 0.
0x5CEC CTLPHY_WRAP__CTL_CFG__CTLCFG_DENALI_PHY_1851 ro
  [23:0] PHY_CAL_RESULT_OBS_0 — Pad calibration results observation values for block 0. READ-ONLY
0x5CF0 CTLPHY_WRAP__CTL_CFG__CTLCFG_DENALI_PHY_1852 ro
  [23:0] PHY_CAL_RESULT2_OBS_0 — Pad calibration results [CKE/RESET_N] observation values for block 0. READ-ONLY
0x5CF4 CTLPHY_WRAP__CTL_CFG__CTLCFG_DENALI_PHY_1853 ro
  [23:0] PHY_CAL_RESULT4_OBS_0 — Pad calibration pass1 shadow results observation values for block 0. READ-ONLY
0x5CF8 CTLPHY_WRAP__CTL_CFG__CTLCFG_DENALI_PHY_1854 ro
  [23:0] PHY_CAL_RESULT5_OBS_0 — Pad calibration pass2 shadow results observation values for block 0. READ-ONLY
0x5CFC CTLPHY_WRAP__CTL_CFG__CTLCFG_DENALI_PHY_1855 ro
  [23:0] PHY_CAL_RESULT6_OBS_0 — Pad calibration internal results observation delta values for block 0. READ-ONLY
0x5D00 CTLPHY_WRAP__CTL_CFG__CTLCFG_DENALI_PHY_1856 access per field
  [30:24] PHY_CAL_CPTR_CNT_0 rw — defines sample capture number in pad calibration process
  [23:0] PHY_CAL_RESULT7_OBS_0 ro — Pad calibration internal results observation delta values for block 0. READ-ONLY
0x5D04 CTLPHY_WRAP__CTL_CFG__CTLCFG_DENALI_PHY_1857
  [24] PHY_CAL_DBG_CFG_0 — defines debug configuration in pad calibration process
  [23:16] PHY_CAL_RCV_FINE_ADJ_0 — defines adjustment for RCV code in pad calibration process
  [15:8] PHY_CAL_PD_FINE_ADJ_0 — defines adjustment for PD code in pad calibration process
  [7:0] PHY_CAL_PU_FINE_ADJ_0 — defines adjustment for PU code in pad calibration process
0x5D08 CTLPHY_WRAP__CTL_CFG__CTLCFG_DENALI_PHY_1858 wo
  [0] SC_PHY_PAD_DBG_CONT_0 — Allows the pad calibration state machine to advance [when in debug mode] for slice 0. Set to 1 to trigger. WRITE-ONLY
0x5D0C CTLPHY_WRAP__CTL_CFG__CTLCFG_DENALI_PHY_1859 ro
  [31:0] PHY_CAL_RESULT3_OBS_0 — Pad calibration results first/last0/1 observation values for block 0. READ-ONLY
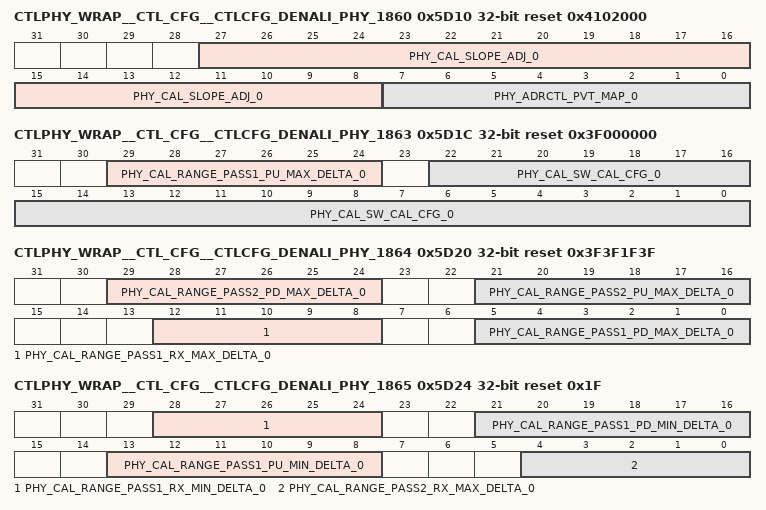
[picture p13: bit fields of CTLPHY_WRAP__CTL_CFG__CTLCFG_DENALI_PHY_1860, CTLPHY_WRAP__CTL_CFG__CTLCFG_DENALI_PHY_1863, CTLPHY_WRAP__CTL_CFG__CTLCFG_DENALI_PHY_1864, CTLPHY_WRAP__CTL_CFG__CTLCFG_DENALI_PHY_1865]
0x5D10 CTLPHY_WRAP__CTL_CFG__CTLCFG_DENALI_PHY_1860 reset 0x4102000
  [27:8] PHY_CAL_SLOPE_ADJ_0 — defines slope configure in pad calibration process
  [7:0] PHY_ADRCTL_PVT_MAP_0 — defines slope configure in pad calibration process
0x5D14 CTLPHY_WRAP__CTL_CFG__CTLCFG_DENALI_PHY_1861 reset 0x41020
  [19:0] PHY_CAL_SLOPE_ADJ_PASS2_0 — defines slope configure for pass2 in pad calibration process
0x5D18 CTLPHY_WRAP__CTL_CFG__CTLCFG_DENALI_PHY_1862 reset 0xC98C98
  [24:0] PHY_CAL_TWO_PASS_CFG_0 — defines cal_en configure in pad calibration process
0x5D1C CTLPHY_WRAP__CTL_CFG__CTLCFG_DENALI_PHY_1863 reset 0x3F000000
  [29:24] PHY_CAL_RANGE_PASS1_PU_MAX_DELTA_0 — Pad calibration pass1 pu results won't update if out of max delta range .
  [22:0] PHY_CAL_SW_CAL_CFG_0 — defines firmware based pad calibration process
0x5D20 CTLPHY_WRAP__CTL_CFG__CTLCFG_DENALI_PHY_1864 reset 0x3F3F1F3F
  [29:24] PHY_CAL_RANGE_PASS2_PD_MAX_DELTA_0 — Pad calibration pass2 pd results won't update if out of max delta range .
  [21:16] PHY_CAL_RANGE_PASS2_PU_MAX_DELTA_0 — Pad calibration pass2 pu results won't update if out of max delta range .
  [12:8] PHY_CAL_RANGE_PASS1_RX_MAX_DELTA_0 — Pad calibration pass1 rx results won't update if out of max delta range .
  [5:0] PHY_CAL_RANGE_PASS1_PD_MAX_DELTA_0 — Pad calibration pass1 pd results won't update if out of max delta range .
0x5D24 CTLPHY_WRAP__CTL_CFG__CTLCFG_DENALI_PHY_1865 reset 0x1F
  [28:24] PHY_CAL_RANGE_PASS1_RX_MIN_DELTA_0 — Pad calibration pass1 rx results won't update if out of min delta range .
  [21:16] PHY_CAL_RANGE_PASS1_PD_MIN_DELTA_0 — Pad calibration pass1 pd results won't update if out of min delta range .
  [13:8] PHY_CAL_RANGE_PASS1_PU_MIN_DELTA_0 — Pad calibration pass1 pu results won't update if out of min delta range .
  [4:0] PHY_CAL_RANGE_PASS2_RX_MAX_DELTA_0 — Pad calibration pass2 rx results won't update if out of max delta range .
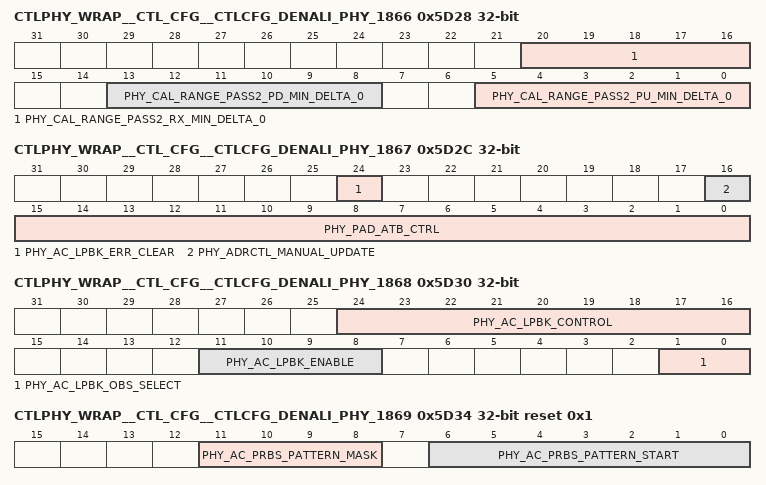
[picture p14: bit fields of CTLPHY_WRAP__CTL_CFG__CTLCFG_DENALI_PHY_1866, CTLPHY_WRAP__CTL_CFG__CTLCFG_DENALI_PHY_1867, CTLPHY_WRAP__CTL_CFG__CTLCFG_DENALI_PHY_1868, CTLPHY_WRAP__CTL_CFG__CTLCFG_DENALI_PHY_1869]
0x5D28 CTLPHY_WRAP__CTL_CFG__CTLCFG_DENALI_PHY_1866
  [20:16] PHY_CAL_RANGE_PASS2_RX_MIN_DELTA_0 — Pad calibration pass2 rx results won't update if out of min delta range .
  [13:8] PHY_CAL_RANGE_PASS2_PD_MIN_DELTA_0 — Pad calibration pass2 pd results won't update if out of min delta range .
  [5:0] PHY_CAL_RANGE_PASS2_PU_MIN_DELTA_0 — Pad calibration pass2 pu results won't update if out of min delta range .
0x5D2C CTLPHY_WRAP__CTL_CFG__CTLCFG_DENALI_PHY_1867 access per field
  [24] PHY_AC_LPBK_ERR_CLEAR wo — Address/control loopback error clear. Set to 1 to clear error. WRITE-ONLY
  [16] PHY_ADRCTL_MANUAL_UPDATE wo — Address/control manual update of target delay lines. Set to 1 to update. WRITE-ONLY
  [15:0] PHY_PAD_ATB_CTRL rw — Pad ATB control settings. Bit [0] is the enable signal. Bits [5:1] are the ATB data signals. Bits [15:8] are the 1 hot select for which pad is selected.
0x5D30 CTLPHY_WRAP__CTL_CFG__CTLCFG_DENALI_PHY_1868
  [24:16] PHY_AC_LPBK_CONTROL — Address/control slice loopback control setting.
  [11:8] PHY_AC_LPBK_ENABLE — Loopback enable for the address/control slices.
  [1:0] PHY_AC_LPBK_OBS_SELECT — Select value to map an individual loopback address/control slice observation register to the global observation register.
0x5D34 CTLPHY_WRAP__CTL_CFG__CTLCFG_DENALI_PHY_1869 reset 0x1
  [11:8] PHY_AC_PRBS_PATTERN_MASK — PRBS7 mask signal for address/control slice.
  [6:0] PHY_AC_PRBS_PATTERN_START — PRBS7 start pattern for address/control slice.
0x5D38 CTLPHY_WRAP__CTL_CFG__CTLCFG_DENALI_PHY_1870 ro
  [31:0] PHY_AC_LPBK_RESULT_OBS — Observation register for the loopback address/control slices. READ-ONLY
0x5D3C CTLPHY_WRAP__CTL_CFG__CTLCFG_DENALI_PHY_1871
  [21:16] PHY_AC_CLK_LPBK_CONTROL — Mem clk block loopback control setting.
  [8] PHY_AC_CLK_LPBK_ENABLE — Loopback enable for mem clk blocks.
  [0] PHY_AC_CLK_LPBK_OBS_SELECT — Select value to map an individual loopback mem clk block observation register to the global observation register.
0x5D40 CTLPHY_WRAP__CTL_CFG__CTLCFG_DENALI_PHY_1872 access per field
  [24] PHY_TOP_PWR_RDC_DISABLE rw — top param power reduction disable.
  [16] PHY_AC_PWR_RDC_DISABLE rw — ac slice power reduction disable.
  [15:0] PHY_AC_CLK_LPBK_RESULT_OBS ro — Observation register for loopback mem clk blocks. READ-ONLY
0x5D44 CTLPHY_WRAP__CTL_CFG__CTLCFG_DENALI_PHY_1873
  [0] PHY_AC_SLV_DLY_CTRL_GATE_DISABLE — ac slice slv_dly_control block power reduction disable.
0x5D48 CTLPHY_WRAP__CTL_CFG__CTLCFG_DENALI_PHY_1874
  [31:0] PHY_DATA_BYTE_ORDER_SEL — Used to define the data slice's byte swap for CA bits 7:0.
0x5D4C CTLPHY_WRAP__CTL_CFG__CTLCFG_DENALI_PHY_1875
  [26:24] PHY_ADR_DISABLE — Disable the unused adr slice to save power.
  [20:16] PHY_CALVL_DEVICE_MAP — Define which device's DQ feedback data bits should be used during CA training
  [8] PHY_LPDDR4_CONNECT — PHY is connected to LPDDR4 devices
  [7:0] PHY_DATA_BYTE_ORDER_SEL_HIGH — Used to define the data slice's byte swap for CA bits 9:8.
0x5D50 CTLPHY_WRAP__CTL_CFG__CTLCFG_DENALI_PHY_1876
  [8n+1:8n] PHY_ADRCTL_MSTR_DLY_ENC_SEL_{n} (n=0..3) — Select adrctl_mstr_dly_enc for the address/control slice {n} .
0x5D54 CTLPHY_WRAP__CTL_CFG__CTLCFG_DENALI_PHY_1877
  [31:0] PHY_DDL_AC_ENABLE — PHY Address/Control DDL BIST mode enable.
0x5D58 CTLPHY_WRAP__CTL_CFG__CTLCFG_DENALI_PHY_1878
  [25:0] PHY_DDL_AC_MODE — PHY Address/Control DDL BIST mode.
0x5D5C CTLPHY_WRAP__CTL_CFG__CTLCFG_DENALI_PHY_1879
  [23:16] PHY_DDL_TRACK_UPD_THRESHOLD_AC — Specify threshold value for PHY init update tracking for AC slice.
  [10:8] PHY_INIT_UPDATE_CONFIG — PHY init update function configuration.
  [5:0] PHY_DDL_AC_MASK — PHY Address/Control DDL BIST mask.
0x5D60 CTLPHY_WRAP__CTL_CFG__CTLCFG_DENALI_PHY_1880
  [26:24] PHY_ERR_STATUS — PHY ERROR information.
  [18:16] PHY_ERR_MASK_EN — PHY ERROR information report mask enable.
  [15:0] PHY_CA_PARITY_ERR_PULSE_MIN — PHY alert_n pulse width minimux value for CA parity error.
{0x4000+4i} CTLPHY_WRAP__CTL_CFG__CTLCFG_DENALI_PHY_{i} ro (i=1881..1884)
  [31:0] PHY_DS{i-1881}_DQS_ERR_COUNTER — PHY DATA SLICE {i-1881} DQS ERROR counter.
0x5D74 CTLPHY_WRAP__CTL_CFG__CTLCFG_DENALI_PHY_1885 access per field reset 0x2
  [27:24] PHY_DS_INIT_COMPLETE_OBS ro — Observation register for dfi_init_complete for data slice. Bit0 is for data_slice0; bit1 is for data_slice 1,... READ-ONLY.
  [19:8] PHY_AC_INIT_COMPLETE_OBS ro — Observation register for dfi_init_complete for adr and ac slice. Bit 0 is for dfi_init_complete for all slices. Bit[7:4] is for adr slice, bit4 is adr_slice0..., if the adr slice number is 3, bit7 is 0. Bit8 is for ac_slice0; bit9 is for ac_slice 1,... READ-ONLY.
  [1:0] PHY_DLL_RST_EN rw — PHY DDL reset software interface enable.
0x5D78 CTLPHY_WRAP__CTL_CFG__CTLCFG_DENALI_PHY_1886
  [28:24] PHY_GRP_SLV_DLY_ENC_OBS_SELECT — Select value to map an individual address/control group slice target delay to the encoded value observation register.
  [16] PHY_AC_DCC_RXCAL_CTRL_GATE_DISABLE — Memory clock bit slice DCC block power reduction disable.
  [8] PHY_ERR_IE — Control the IE signal of IO error pad.
  [0] PHY_UPDATE_MASK — Control to disable the generation of dfi_phyupd_req and use of dfi_ctrlupd_req. If this is 0 the PHY is normal mode; if this is 1, the PHY will not respond to dfi_ctrlupd_req or not to send dfi_phyupd_req
0x5D7C CTLPHY_WRAP__CTL_CFG__CTLCFG_DENALI_PHY_1887 access per field
  [26:24] PHY_GRP_SHIFT_OBS ro — Observation register for the address/control group automatic half cycle and cycle shift values. READ-ONLY
  [18:8] PHY_GRP_SLV_DLY_ENC_OBS ro — Observation register for all address/control group slice target delay encoded values. READ-ONLY
  [3:0] PHY_GRP_SHIFT_OBS_SELECT rw — Select value to map an individual address/control group slice automatic cycle/half_cycle shift settings to the observation register.
0x5D80 CTLPHY_WRAP__CTL_CFG__CTLCFG_DENALI_PHY_1888
  [17:0] PHY_PAD_CAL_IO_CFG_0 — Pad calibration Controls PCLK/PARK pin and vref switch.
0x5D84 CTLPHY_WRAP__CTL_CFG__CTLCFG_DENALI_PHY_1889
  [26:24] PHY_PAD_ACS_RX_PCLK_CLK_SEL — Controls rx_pclk clk selection for acs pad.
  [17:0] PHY_PAD_ACS_IO_CFG — Controls PCLK/PARK pin for acs pad.
0x5D88 CTLPHY_WRAP__CTL_CFG__CTLCFG_DENALI_PHY_1890
  [0] PHY_PLL_BYPASS — PHY clock PLL bypass select.
0x5D8C CTLPHY_WRAP__CTL_CFG__CTLCFG_DENALI_PHY_1891
  [16] PHY_LOW_FREQ_SEL — Enables the PHY to enter/exit the PLL domain from the negative clock edge. Set to 1 at low frequencies to enable.
  [12:0] PHY_PLL_CTRL — PHY clock PLL controls.
0x5D90 CTLPHY_WRAP__CTL_CFG__CTLCFG_DENALI_PHY_1892
  [27:24] PHY_CSLVL_DLY_STEP — Sets the delay step size plus 1 during CS training.
  [19:16] PHY_CSLVL_CAPTURE_CNT — Defines the number of samples to take at each GRP target delay setting during CS training.
  [11:0] PHY_PAD_VREF_CTRL_AC — Pad VREF control settings for the address/control.
0x5D94 CTLPHY_WRAP__CTL_CFG__CTLCFG_DENALI_PHY_1893
  [24] PHY_LVL_MEAS_DLY_STEP_ENABLE — Enables the phy_adr_meas_dly_step_value to be used instead of the phy_cslvl_dly_step parameter.
  [16] PHY_SW_CSLVL_DVW_MIN_EN — Enables the software override data valid window size during CS training.
  [9:0] PHY_SW_CSLVL_DVW_MIN — Sets the software override data valid window size during CS training.
0x5D98 CTLPHY_WRAP__CTL_CFG__CTLCFG_DENALI_PHY_1894
  [26:16] PHY_GRP1_SLAVE_DELAY_0 — Address slice target delay setting for address slice 1.
  [10:0] PHY_GRP0_SLAVE_DELAY_0 — Address slice target delay setting for address slice 0.
0x5D9C CTLPHY_WRAP__CTL_CFG__CTLCFG_DENALI_PHY_1895
  [26:16] PHY_GRP3_SLAVE_DELAY_0 — Address slice target delay setting for address slice 3.
  [10:0] PHY_GRP2_SLAVE_DELAY_0 — Address slice target delay setting for address slice 2.
0x5DA0 CTLPHY_WRAP__CTL_CFG__CTLCFG_DENALI_PHY_1896
  [26:16] PHY_GRP1_SLAVE_DELAY_1 — Address slice target delay setting for address slice 1.
  [10:0] PHY_GRP0_SLAVE_DELAY_1 — Address slice target delay setting for address slice 0.
0x5DA4 CTLPHY_WRAP__CTL_CFG__CTLCFG_DENALI_PHY_1897
  [26:16] PHY_GRP3_SLAVE_DELAY_1 — Address slice target delay setting for address slice 3.
  [10:0] PHY_GRP2_SLAVE_DELAY_1 — Address slice target delay setting for address slice 2.
0x5DA8 CTLPHY_WRAP__CTL_CFG__CTLCFG_DENALI_PHY_1898
  [26:16] PHY_GRP1_SLAVE_DELAY_2 — Address slice target delay setting for address slice 1.
  [10:0] PHY_GRP0_SLAVE_DELAY_2 — Address slice target delay setting for address slice 0.
0x5DAC CTLPHY_WRAP__CTL_CFG__CTLCFG_DENALI_PHY_1899
  [26:16] PHY_GRP3_SLAVE_DELAY_2 — Address slice target delay setting for address slice 3.
  [10:0] PHY_GRP2_SLAVE_DELAY_2 — Address slice target delay setting for address slice 2.
{0x4000+4i} CTLPHY_WRAP__CTL_CFG__CTLCFG_DENALI_PHY_{i} (i=1900..1903)
  [10:0] PHY_GRP{i-1900}_SLAVE_DELAY_3 — Address slice target delay setting for address slice {i-1900}.
0x5DC0 CTLPHY_WRAP__CTL_CFG__CTLCFG_DENALI_PHY_1904
  [2:0] PHY_CLK_DC_CAL_CLK_SEL — Determines DCC CAL clock.
0x5DC4 CTLPHY_WRAP__CTL_CFG__CTLCFG_DENALI_PHY_1905 reset 0xFF
  [29:0] PHY_PAD_FDBK_DRIVE — Controls drive settings for gate feedback pads.
0x5DC8 CTLPHY_WRAP__CTL_CFG__CTLCFG_DENALI_PHY_1906 reset 0xFF
  [17:0] PHY_PAD_FDBK_DRIVE2 — Controls drive settings [enslice/boost] for gate feedback pads.
0x5DCC CTLPHY_WRAP__CTL_CFG__CTLCFG_DENALI_PHY_1907
  [30:0] PHY_PAD_DATA_DRIVE — Controls drive settings for data pads.
0x5DD0 CTLPHY_WRAP__CTL_CFG__CTLCFG_DENALI_PHY_1908
  [31:0] PHY_PAD_DQS_DRIVE — Controls drive settings for dqs pads.
0x5DD4 CTLPHY_WRAP__CTL_CFG__CTLCFG_DENALI_PHY_1909 reset 0xFF
  [29:0] PHY_PAD_ADDR_DRIVE — Controls drive settings for the address/control pads.
0x5DD8 CTLPHY_WRAP__CTL_CFG__CTLCFG_DENALI_PHY_1910 reset 0xFFFF00
  [27:0] PHY_PAD_ADDR_DRIVE2 — Controls drive settings for the address/control pads.
0x5DDC CTLPHY_WRAP__CTL_CFG__CTLCFG_DENALI_PHY_1911 reset 0xFF
  [31:0] PHY_PAD_CLK_DRIVE — Controls drive settings for clock pads.
0x5DE0 CTLPHY_WRAP__CTL_CFG__CTLCFG_DENALI_PHY_1912 reset 0xFF
  [18:0] PHY_PAD_CLK_DRIVE2 — Controls drive settings for clock pads.
0x5DE4 CTLPHY_WRAP__CTL_CFG__CTLCFG_DENALI_PHY_1913 reset 0xFF
  [29:0] PHY_PAD_ERR_DRIVE — Controls drive settings for error pads.
0x5DE8 CTLPHY_WRAP__CTL_CFG__CTLCFG_DENALI_PHY_1914 reset 0xFFFF00
  [27:0] PHY_PAD_ERR_DRIVE2 — Controls drive settings for error pads.
0x5DEC CTLPHY_WRAP__CTL_CFG__CTLCFG_DENALI_PHY_1915 reset 0xFF
  [29:0] PHY_PAD_CKE_DRIVE — Controls drive settings for cke pads.
0x5DF0 CTLPHY_WRAP__CTL_CFG__CTLCFG_DENALI_PHY_1916 reset 0x1FFFF00
  [27:0] PHY_PAD_CKE_DRIVE2 — Controls drive settings for cke pads.
0x5DF4 CTLPHY_WRAP__CTL_CFG__CTLCFG_DENALI_PHY_1917 reset 0xFF
  [29:0] PHY_PAD_RST_DRIVE — Controls drive settings for reset_n pads.
0x5DF8 CTLPHY_WRAP__CTL_CFG__CTLCFG_DENALI_PHY_1918 reset 0x1FFFF00
  [27:0] PHY_PAD_RST_DRIVE2 — Controls drive settings for reset_n pads.
0x5DFC CTLPHY_WRAP__CTL_CFG__CTLCFG_DENALI_PHY_1919 reset 0xFF
  [29:0] PHY_PAD_CS_DRIVE — Controls drive settings for cs pads.
0x5E00 CTLPHY_WRAP__CTL_CFG__CTLCFG_DENALI_PHY_1920 reset 0x1FFFF00
  [27:0] PHY_PAD_CS_DRIVE2 — Controls drive settings for cs pads.
0x5E04 CTLPHY_WRAP__CTL_CFG__CTLCFG_DENALI_PHY_1921 reset 0xFF
  [29:0] PHY_PAD_ODT_DRIVE — Controls drive settings for odt pads.
0x5E08 CTLPHY_WRAP__CTL_CFG__CTLCFG_DENALI_PHY_1922 reset 0x1FFFF00
  [27:0] PHY_PAD_ODT_DRIVE2 — Controls drive settings for odt pads.
0x5E0C CTLPHY_WRAP__CTL_CFG__CTLCFG_DENALI_PHY_1923
  [30:24] PHY_CAL_SETTLING_PRD_0 — Number of clock cycles to extend dfi_phyupd_req after the ack is received for settling of final values
  [23:8] PHY_CAL_VREF_SWITCH_TIMER_0 — The settling time for a switch in VREF during IO pad calibration.
  [2:0] PHY_CAL_CLK_SELECT_0 — Pad calibration pad clock frequency select setting for block 0.
